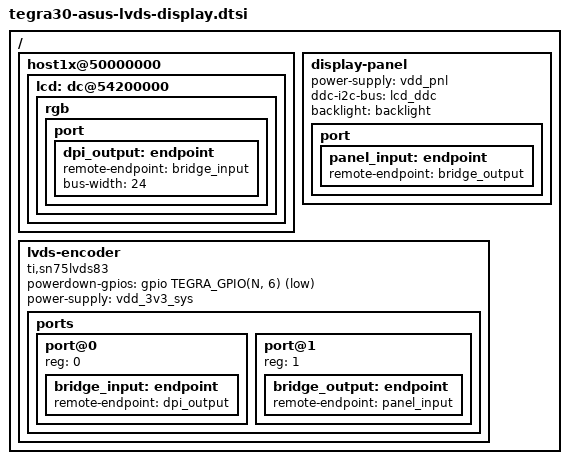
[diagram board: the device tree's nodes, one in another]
// SPDX-License-Identifier: GPL-2.0

/* This dtsi file describes parts common for Asus T30 devices with a LVDS panel. */

#include <dt-bindings/gpio/tegra-gpio.h>

/ {
	host1x@50000000 {
		lcd: dc@54200000 {
			rgb {
				status = "okay";

				port {
					dpi_output: endpoint {
						remote-endpoint = <&bridge_input>;
						bus-width = <24>;
					};
				};
			};
		};
	};

	display-panel {
		power-supply = <&vdd_pnl>;
		ddc-i2c-bus = <&lcd_ddc>;
		backlight = <&backlight>;

		port {
			panel_input: endpoint {
				remote-endpoint = <&bridge_output>;
			};
		};
	};

	/* Texas Instruments SN75LVDS83B LVDS Transmitter */
	lvds-encoder {
		compatible = "ti,sn75lvds83", "lvds-encoder";

		powerdown-gpios = <&gpio TEGRA_GPIO(N, 6) GPIO_ACTIVE_LOW>;
		power-supply = <&vdd_3v3_sys>;

		ports {
			#address-cells = <1>;
			#size-cells = <0>;

			port@0 {
				reg = <0>;

				bridge_input: endpoint {
					remote-endpoint = <&dpi_output>;
				};
			};

			port@1 {
				reg = <1>;

				bridge_output: endpoint {
					remote-endpoint = <&panel_input>;
				};
			};
		};
	};
};
